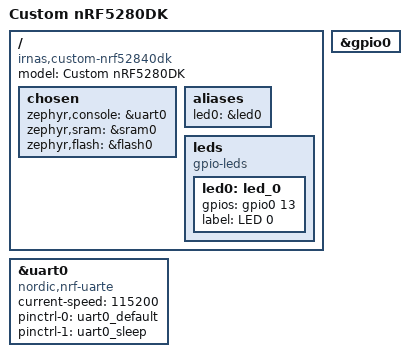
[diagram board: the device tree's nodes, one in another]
/*
 * Copyright (c) 2021 Nordic Semiconductor ASA
 * SPDX-License-Identifier: Apache-2.0
 */

/dts-v1/;
#include <nordic/nrf52840_qiaa.dtsi>
#include "custom_nrf52840dk-pinctrl.dtsi"

/ {
	model = "Custom nRF5280DK";
	compatible = "irnas,custom-nrf52840dk";

	chosen {
		zephyr,console = &uart0;
		zephyr,sram = &sram0;
		zephyr,flash = &flash0;
	};
    aliases {
            led0 = &led0;
        };

        leds {
            compatible = "gpio-leds";
            led0: led_0 {
                gpios = <&gpio0 13 GPIO_ACTIVE_HIGH>;
                label = "LED 0";
            };
        };
};

&gpio0 {
	status = "okay";
};

&uart0 {
	compatible = "nordic,nrf-uarte";
	status = "okay";

	current-speed = <115200>;
	pinctrl-0 = <&uart0_default>;
	pinctrl-1 = <&uart0_sleep>;
	pinctrl-names = "default", "sleep";
};
